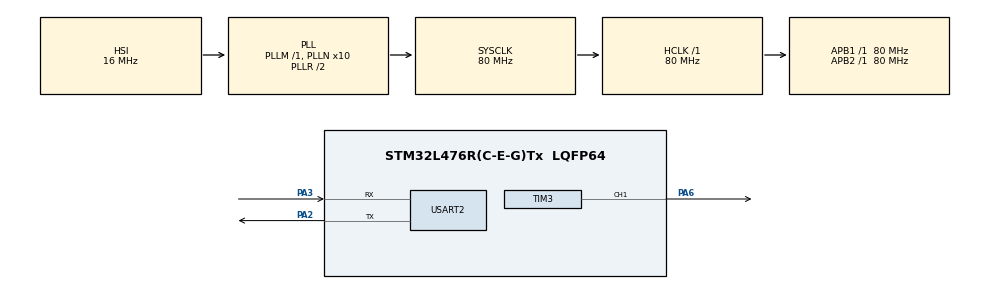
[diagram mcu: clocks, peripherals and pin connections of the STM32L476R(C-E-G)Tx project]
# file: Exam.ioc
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Mcu.Family=STM32L4
Mcu.Name=STM32L476R(C-E-G)Tx
Mcu.Package=LQFP64
NVIC.PriorityGroup=NVIC_PRIORITYGROUP_4
NVIC.USART2_IRQn=true\:0\:0\:false\:false\:true\:true\:true\:true
PA2.Mode=Asynchronous
PA2.Signal=USART2_TX
PA3.Mode=Asynchronous
PA3.Signal=USART2_RX
PA6.Signal=S_TIM3_CH1
ProjectManager.HeapSize=0x200
ProjectManager.StackSize=0x400
ProjectManager.TargetToolchain=STM32CubeIDE
RCC.ADCFreq_Value=64000000
RCC.AHBFreq_Value=80000000
RCC.APB1Freq_Value=80000000
RCC.APB1TimFreq_Value=80000000
RCC.APB2Freq_Value=80000000
RCC.APB2TimFreq_Value=80000000
RCC.CortexFreq_Value=80000000
RCC.HCLKFreq_Value=80000000
RCC.HSE_VALUE=8000000
RCC.HSI_VALUE=16000000
RCC.LSE_VALUE=32768
RCC.MSI_VALUE=4000000
RCC.PLLN=10
RCC.PLLSourceVirtual=RCC_PLLSOURCE_HSI
RCC.PREFETCH_ENABLE=1
RCC.SYSCLKFreq_VALUE=80000000
RCC.SYSCLKSource=RCC_SYSCLKSOURCE_PLLCLK
RCC.USBFreq_Value=64000000
RCC.VCOOutputFreq_Value=160000000
SH.S_TIM3_CH1.0=TIM3_CH1,PWM Generation1 CH1
TIM3.Channel-PWM\ Generation1\ CH1=TIM_CHANNEL_1
TIM3.Period=1000-1
TIM3.Prescaler=80-1
USART2.VirtualMode-Asynchronous=VM_ASYNC
VP_TIM3_VS_ClockSourceINT.Mode=Internal
board=NUCLEO-L476RG

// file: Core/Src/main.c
/* USER CODE BEGIN Header */
/**
  ******************************************************************************
  * @file           : main.c
  * @brief          : Main program body
  ******************************************************************************
  * @attention
  *
  * Copyright (c) 2023 STMicroelectronics.
  * All rights reserved.
  *
  * This software is licensed under terms that can be found in the LICENSE file
  * in the root directory of this software component.
  * If no LICENSE file comes with this software, it is provided AS-IS.
  *
  ******************************************************************************
  */
/* USER CODE END Header */
#include "main.h"

TIM_HandleTypeDef htim3;

UART_HandleTypeDef huart2;

void SystemClock_Config(void);
static void MX_GPIO_Init(void);
static void MX_TIM3_Init(void);
static void MX_USART2_UART_Init(void);

/* USER CODE BEGIN 0 */
/* This variable stores the value of the duty cycle in order to
change the brightness of the LED*/
uint8_t value_duty[4];
/* This variable stores the maximum value of the duty cycle*/
uint16_t max_value_duty = 0;
uint16_t new_value = 0;
/* USER CODE END 0 */

int main(void)
{

  /* MCU Configuration--------------------------------------------------------*/

  /* Reset of all peripherals, Initializes the Flash interface and the Systick. */
  HAL_Init();

  /* Configure the system clock */
  SystemClock_Config();

  /* Initialize all configured peripherals */
  MX_GPIO_Init();
  MX_TIM3_Init();
  MX_USART2_UART_Init();
  /* USER CODE BEGIN 2 */
  // Start the PWM of the timer3 in the channel 1.
  HAL_TIM_PWM_Start(&htim3, TIM_CHANNEL_1);

  // We set the variable equal to the register ARR
  max_value_duty = htim3.Instance->ARR;
  /* USER CODE END 2 */

  /* Infinite loop */
  /* USER CODE BEGIN WHILE */
  // First we should receive the value that is send with uart to set the value of the duty
  HAL_UART_Receive_IT(&huart2, &value_duty[0,1], sizeof(value_duty));
  while (1)
  {
	  	// We check if the value of duty received with uart is 00 between 99
	  	// We convert the value so we can compare
	  	new_value = value_duty[0] - '0';
	  	new_value = (new_value *10) + (value_duty[0] - '0');
	  	if(new_value > 0 && new_value < 100)
	  	{
	  		htim3.Instance->CCR1 = new_value;
	  	}
	  	/* We send the value of the current duty cycle with UART
	  	to do this we set the uart we are using in this case the second one
	  	then we specify our value and its size, and finally we set the delay*/
		HAL_UART_Transmit(&huart2, &value_duty[0,1] , 2, 1000);
		// We change the brigthness of the led with 1 ms delay//
		HAL_Delay(1000);

    /* USER CODE END WHILE */

  }
}

void SystemClock_Config(void)
{
  RCC_OscInitTypeDef RCC_OscInitStruct = {0};
  RCC_ClkInitTypeDef RCC_ClkInitStruct = {0};

  /** Configure the main internal regulator output voltage
  */
  if (HAL_PWREx_ControlVoltageScaling(PWR_REGULATOR_VOLTAGE_SCALE1) != HAL_OK)
  {
    Error_Handler();
  }

  /** Initializes the RCC Oscillators according to the specified parameters
  * in the RCC_OscInitTypeDef structure.
  */
  RCC_OscInitStruct.OscillatorType = RCC_OSCILLATORTYPE_HSI;
  RCC_OscInitStruct.HSIState = RCC_HSI_ON;
  RCC_OscInitStruct.HSICalibrationValue = RCC_HSICALIBRATION_DEFAULT;
  RCC_OscInitStruct.PLL.PLLState = RCC_PLL_ON;
  RCC_OscInitStruct.PLL.PLLSource = RCC_PLLSOURCE_HSI;
  RCC_OscInitStruct.PLL.PLLM = 1;
  RCC_OscInitStruct.PLL.PLLN = 10;
  RCC_OscInitStruct.PLL.PLLP = RCC_PLLP_DIV7;
  RCC_OscInitStruct.PLL.PLLQ = RCC_PLLQ_DIV2;
  RCC_OscInitStruct.PLL.PLLR = RCC_PLLR_DIV2;
  if (HAL_RCC_OscConfig(&RCC_OscInitStruct) != HAL_OK)
  {
    Error_Handler();
  }

  /** Initializes the CPU, AHB and APB buses clocks
  */
  RCC_ClkInitStruct.ClockType = RCC_CLOCKTYPE_HCLK|RCC_CLOCKTYPE_SYSCLK
                              |RCC_CLOCKTYPE_PCLK1|RCC_CLOCKTYPE_PCLK2;
  RCC_ClkInitStruct.SYSCLKSource = RCC_SYSCLKSOURCE_PLLCLK;
  RCC_ClkInitStruct.AHBCLKDivider = RCC_SYSCLK_DIV1;
  RCC_ClkInitStruct.APB1CLKDivider = RCC_HCLK_DIV1;
  RCC_ClkInitStruct.APB2CLKDivider = RCC_HCLK_DIV1;

  if (HAL_RCC_ClockConfig(&RCC_ClkInitStruct, FLASH_LATENCY_4) != HAL_OK)
  {
    Error_Handler();
  }
}

static void MX_TIM3_Init(void)
{

  TIM_ClockConfigTypeDef sClockSourceConfig = {0};
  TIM_MasterConfigTypeDef sMasterConfig = {0};
  TIM_OC_InitTypeDef sConfigOC = {0};

  htim3.Instance = TIM3;
  htim3.Init.Prescaler = 80-1;
  htim3.Init.CounterMode = TIM_COUNTERMODE_UP;
  htim3.Init.Period = 1000-1;
  htim3.Init.ClockDivision = TIM_CLOCKDIVISION_DIV1;
  htim3.Init.AutoReloadPreload = TIM_AUTORELOAD_PRELOAD_DISABLE;
  if (HAL_TIM_Base_Init(&htim3) != HAL_OK)
  {
    Error_Handler();
  }
  sClockSourceConfig.ClockSource = TIM_CLOCKSOURCE_INTERNAL;
  if (HAL_TIM_ConfigClockSource(&htim3, &sClockSourceConfig) != HAL_OK)
  {
    Error_Handler();
  }
  if (HAL_TIM_PWM_Init(&htim3) != HAL_OK)
  {
    Error_Handler();
  }
  sMasterConfig.MasterOutputTrigger = TIM_TRGO_RESET;
  sMasterConfig.MasterSlaveMode = TIM_MASTERSLAVEMODE_DISABLE;
  if (HAL_TIMEx_MasterConfigSynchronization(&htim3, &sMasterConfig) != HAL_OK)
  {
    Error_Handler();
  }
  sConfigOC.OCMode = TIM_OCMODE_PWM1;
  sConfigOC.Pulse = 0;
  sConfigOC.OCPolarity = TIM_OCPOLARITY_HIGH;
  sConfigOC.OCFastMode = TIM_OCFAST_DISABLE;
  if (HAL_TIM_PWM_ConfigChannel(&htim3, &sConfigOC, TIM_CHANNEL_1) != HAL_OK)
  {
    Error_Handler();
  }
  HAL_TIM_MspPostInit(&htim3);

}

static void MX_USART2_UART_Init(void)
{

  huart2.Instance = USART2;
  huart2.Init.BaudRate = 115200;
  huart2.Init.WordLength = UART_WORDLENGTH_8B;
  huart2.Init.StopBits = UART_STOPBITS_1;
  huart2.Init.Parity = UART_PARITY_NONE;
  huart2.Init.Mode = UART_MODE_TX_RX;
  huart2.Init.HwFlowCtl = UART_HWCONTROL_NONE;
  huart2.Init.OverSampling = UART_OVERSAMPLING_16;
  huart2.Init.OneBitSampling = UART_ONE_BIT_SAMPLE_DISABLE;
  huart2.AdvancedInit.AdvFeatureInit = UART_ADVFEATURE_NO_INIT;
  if (HAL_UART_Init(&huart2) != HAL_OK)
  {
    Error_Handler();
  }

}

static void MX_GPIO_Init(void)
{

  /* GPIO Ports Clock Enable */
  __HAL_RCC_GPIOA_CLK_ENABLE();

}

/* USER CODE BEGIN 4 */

// Callback for interruption
void HAL_UART_RxCpltCallback(UART_HandleTypeDef *huart)
{
	HAL_UART_Receive_IT(&huart2, &value_duty[0,1], sizeof(value_duty));
}

/* USER CODE END 4 */

void Error_Handler(void)
{
  __disable_irq();
  while (1)
  {
  }
}
